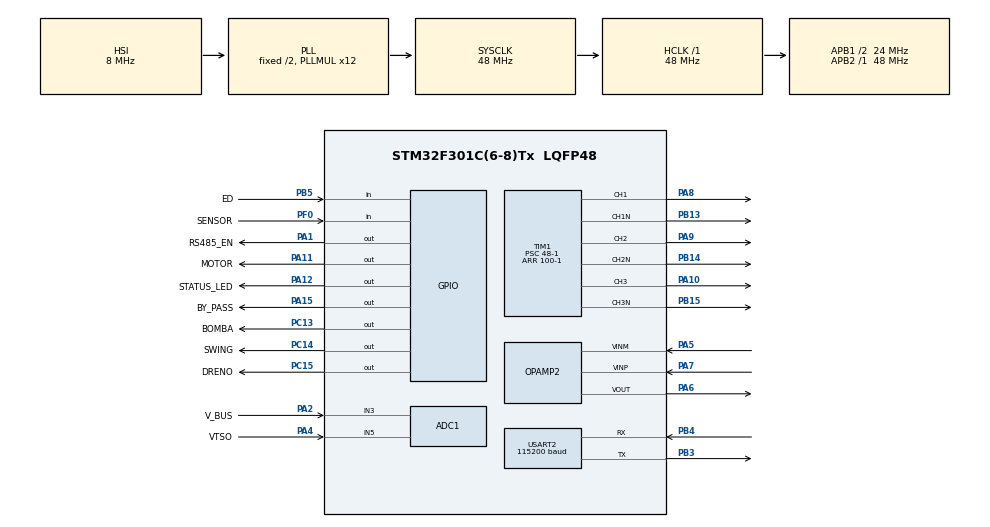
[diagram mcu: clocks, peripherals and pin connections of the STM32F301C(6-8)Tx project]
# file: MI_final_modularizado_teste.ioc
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ADC1.Channel-0\#ChannelRegularConversion=ADC_CHANNEL_5
ADC1.NbrOfConversionFlag=1
ADC1.Offset-0\#ChannelRegularConversion=0
ADC1.OffsetNumber-0\#ChannelRegularConversion=ADC_OFFSET_NONE
ADC1.Rank-0\#ChannelRegularConversion=1
ADC1.SamplingTime-0\#ChannelRegularConversion=ADC_SAMPLETIME_181CYCLES_5
ADC1.SamplingTimeOPAMP-0\#ChannelRegularConversion=ADC_SAMPLETIME_181CYCLES_5
ADC1.master=1
Dma.Request0=USART2_RX
Dma.USART2_RX.0.Direction=DMA_PERIPH_TO_MEMORY
Dma.USART2_RX.0.Instance=DMA1_Channel6
Dma.USART2_RX.0.MemDataAlignment=DMA_MDATAALIGN_BYTE
Dma.USART2_RX.0.MemInc=DMA_MINC_ENABLE
Dma.USART2_RX.0.Mode=DMA_NORMAL
Dma.USART2_RX.0.PeriphDataAlignment=DMA_PDATAALIGN_BYTE
Dma.USART2_RX.0.PeriphInc=DMA_PINC_DISABLE
Dma.USART2_RX.0.Priority=DMA_PRIORITY_LOW
Mcu.Family=STM32F3
Mcu.Name=STM32F301C(6-8)Tx
Mcu.Package=LQFP48
NVIC.DMA1_Channel6_IRQn=true\:0\:0\:false\:false\:true\:false\:true\:true
NVIC.PriorityGroup=NVIC_PRIORITYGROUP_4
NVIC.TIM1_UP_TIM16_IRQn=true\:0\:0\:false\:false\:true\:true\:true\:true
NVIC.TIM2_IRQn=true\:0\:0\:false\:false\:true\:true\:true\:true
NVIC.USART2_IRQn=true\:0\:0\:false\:false\:true\:true\:true\:true
PA1.GPIO_Label=RS485_EN
PA1.Signal=GPIO_Output
PA10.Signal=S_TIM1_CH3
PA11.GPIO_Label=MOTOR
PA11.GPIO_PuPd=GPIO_PULLDOWN
PA11.Signal=GPIO_Output
PA12.GPIO_Label=STATUS_LED
PA12.GPIO_PuPd=GPIO_NOPULL
PA12.Signal=GPIO_Output
PA13.Mode=Serial_Wire
PA13.Signal=SYS_JTMS-SWDIO
PA14.Mode=Serial_Wire
PA14.Signal=SYS_JTCK-SWCLK
PA15.GPIO_Label=BY_PASS
PA15.Signal=GPIO_Output
PA2.GPIO_Label=V_BUS
PA2.Mode=IN3-Single-Ended
PA2.Signal=ADC1_IN3
PA4.GPIO_Label=VTSO
PA4.Mode=IN5-Single-Ended
PA4.Signal=ADC1_IN5
PA5.Mode=Standalone
PA5.Signal=OPAMP2_VINM
PA6.Signal=SharedAnalog_PA6
PA7.Mode=Standalone
PA7.Signal=OPAMP2_VINP
PA8.Signal=S_TIM1_CH1
PA9.Signal=S_TIM1_CH2
PB13.Mode=PWM Generation1 CH1 CH1N
PB13.Signal=TIM1_CH1N
PB14.Mode=PWM Generation2 CH2 CH2N
PB14.Signal=TIM1_CH2N
PB15.Mode=PWM Generation3 CH3 CH3N
PB15.Signal=TIM1_CH3N
PB3.Mode=Asynchronous
PB3.Signal=USART2_TX
PB4.Mode=Asynchronous
PB4.Signal=USART2_RX
PB5.GPIO_Label=ED
PB5.Signal=GPIO_Input
PC13.GPIO_Label=BOMBA
PC13.GPIO_PuPd=GPIO_PULLDOWN
PC13.Signal=GPIO_Output
PC14\ -\ OSC32_IN.GPIO_Label=SWING
PC14\ -\ OSC32_IN.GPIO_PuPd=GPIO_PULLDOWN
PC14\ -\ OSC32_IN.Signal=GPIO_Output
PC15\ -\ OSC32_OUT.GPIO_Label=DRENO
PC15\ -\ OSC32_OUT.GPIO_PuPd=GPIO_PULLDOWN
PC15\ -\ OSC32_OUT.Signal=GPIO_Output
PF0-OSC_IN.GPIO_Label=SENSOR
PF0-OSC_IN.GPIO_PuPd=GPIO_PULLDOWN
PF0-OSC_IN.Signal=GPIO_Input
ProjectManager.HeapSize=0x200
ProjectManager.StackSize=0x400
ProjectManager.TargetToolchain=STM32CubeIDE
RCC.AHBFreq_Value=48000000
RCC.APB1CLKDivider=RCC_HCLK_DIV2
RCC.APB1Freq_Value=24000000
RCC.APB1TimFreq_Value=48000000
RCC.APB2Freq_Value=48000000
RCC.APB2TimFreq_Value=48000000
RCC.CortexFreq_Value=48000000
RCC.DATA_CACHE_ENABLE=1
RCC.HCLKFreq_Value=48000000
RCC.HSE_VALUE=8000000
RCC.HSI_VALUE=8000000
RCC.INSTRUCTION_CACHE_ENABLE=1
RCC.LSE_Drive_CapabilityArg=+LSE_Drive_Capability
RCC.LSE_VALUE=32768
RCC.PLLMUL=RCC_PLL_MUL12
RCC.SYSCLKFreq_VALUE=48000000
RCC.SYSCLKSourceVirtual=RCC_SYSCLKSOURCE_PLLCLK
SH.S_TIM1_CH1.0=TIM1_CH1,PWM Generation1 CH1 CH1N
SH.S_TIM1_CH2.0=TIM1_CH2,PWM Generation2 CH2 CH2N
SH.S_TIM1_CH3.0=TIM1_CH3,PWM Generation3 CH3 CH3N
SH.SharedAnalog_PA6.0=ADC1_IN10
SH.SharedAnalog_PA6.1=OPAMP2_VOUT,Standalone
TIM1.AutoReloadPreload=TIM_AUTORELOAD_PRELOAD_ENABLE
TIM1.Channel-PWM\ Generation1\ CH1\ CH1N=TIM_CHANNEL_1
TIM1.Channel-PWM\ Generation2\ CH2\ CH2N=TIM_CHANNEL_2
TIM1.Channel-PWM\ Generation3\ CH3\ CH3N=TIM_CHANNEL_3
TIM1.DeadTime=96
TIM1.Period=100-1
TIM1.Prescaler=48-1
TIM1.Pulse-PWM\ Generation1\ CH1\ CH1N=50
TIM1.Pulse-PWM\ Generation2\ CH2\ CH2N=50
TIM1.Pulse-PWM\ Generation3\ CH3\ CH3N=50
TIM16.Period=10000-1
TIM16.Prescaler=4800-1
TIM2.AutoReloadPreload=TIM_AUTORELOAD_PRELOAD_ENABLE
TIM2.Period=100-1
TIM2.Prescaler=48-1
USART2.BaudRate=115200
USART2.Parity=PARITY_EVEN
USART2.VirtualMode-Asynchronous=VM_ASYNC
USART2.WordLength=WORDLENGTH_9B
VP_ADC1_OPAMP_OUT2.Mode=IN10-OPAMP2-Single-Ended
VP_TIM16_VS_ClockSourceINT.Mode=Enable_Timer
VP_TIM2_VS_ClockSourceINT.Mode=Internal
board=custom

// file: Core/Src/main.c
/* USER CODE BEGIN Header */
/**
  ******************************************************************************
  * @file           : main.c
  * @brief          : Main program body
  ******************************************************************************
  * @attention
  *
  * Copyright (c) 2026 STMicroelectronics.
  * All rights reserved.
  *
  * This software is licensed under terms that can be found in the LICENSE file
  * in the root directory of this software component.
  * If no LICENSE file comes with this software, it is provided AS-IS.
  *
  ******************************************************************************
  */
/* USER CODE END Header */
#include "main.h"
#include "adc.h"
#include "dma.h"
#include "opamp.h"
#include "tim.h"
#include "usart.h"
#include "gpio.h"

/* USER CODE BEGIN Includes */
#include "mi_app.h"
/* USER CODE END Includes */

void SystemClock_Config(void);

int main(void)
{

  /* MCU Configuration--------------------------------------------------------*/

  /* Reset of all peripherals, Initializes the Flash interface and the Systick. */
  HAL_Init();

  /* Configure the system clock */
  SystemClock_Config();

  /* Initialize all configured peripherals */
  MX_GPIO_Init();
  MX_DMA_Init();
  MX_TIM1_Init();
  MX_TIM2_Init();
  MX_TIM16_Init();
  MX_USART2_UART_Init();
  MX_ADC1_Init();
  MX_OPAMP2_Init();
  /* USER CODE BEGIN 2 */
  mi_app_init();
  /* USER CODE END 2 */

  /* Infinite loop */
  /* USER CODE BEGIN WHILE */
  while (1)
  {
	mi_app_process();
    /* USER CODE END WHILE */

  }
}

void SystemClock_Config(void)
{
  RCC_OscInitTypeDef RCC_OscInitStruct = {0};
  RCC_ClkInitTypeDef RCC_ClkInitStruct = {0};
  RCC_PeriphCLKInitTypeDef PeriphClkInit = {0};

  /** Initializes the RCC Oscillators according to the specified parameters
  * in the RCC_OscInitTypeDef structure.
  */
  RCC_OscInitStruct.OscillatorType = RCC_OSCILLATORTYPE_HSI;
  RCC_OscInitStruct.HSIState = RCC_HSI_ON;
  RCC_OscInitStruct.HSICalibrationValue = RCC_HSICALIBRATION_DEFAULT;
  RCC_OscInitStruct.PLL.PLLState = RCC_PLL_ON;
  RCC_OscInitStruct.PLL.PLLSource = RCC_PLLSOURCE_HSI;
  RCC_OscInitStruct.PLL.PLLMUL = RCC_PLL_MUL12;
  if (HAL_RCC_OscConfig(&RCC_OscInitStruct) != HAL_OK)
  {
    Error_Handler();
  }

  /** Initializes the CPU, AHB and APB buses clocks
  */
  RCC_ClkInitStruct.ClockType = RCC_CLOCKTYPE_HCLK|RCC_CLOCKTYPE_SYSCLK
                              |RCC_CLOCKTYPE_PCLK1|RCC_CLOCKTYPE_PCLK2;
  RCC_ClkInitStruct.SYSCLKSource = RCC_SYSCLKSOURCE_PLLCLK;
  RCC_ClkInitStruct.AHBCLKDivider = RCC_SYSCLK_DIV1;
  RCC_ClkInitStruct.APB1CLKDivider = RCC_HCLK_DIV2;
  RCC_ClkInitStruct.APB2CLKDivider = RCC_HCLK_DIV1;

  if (HAL_RCC_ClockConfig(&RCC_ClkInitStruct, FLASH_LATENCY_1) != HAL_OK)
  {
    Error_Handler();
  }
  PeriphClkInit.PeriphClockSelection = RCC_PERIPHCLK_TIM1|RCC_PERIPHCLK_TIM16
                              |RCC_PERIPHCLK_ADC1;
  PeriphClkInit.Tim1ClockSelection = RCC_TIM1CLK_HCLK;
  PeriphClkInit.Tim16ClockSelection = RCC_TIM16CLK_HCLK;
  PeriphClkInit.Adc1ClockSelection = RCC_ADC1PLLCLK_DIV1;

  if (HAL_RCCEx_PeriphCLKConfig(&PeriphClkInit) != HAL_OK)
  {
    Error_Handler();
  }
}

/* USER CODE BEGIN 4 */
void HAL_TIM_PeriodElapsedCallback(TIM_HandleTypeDef *htim)
{
  mi_app_on_period_elapsed(htim);
}
/* USER CODE END 4 */

void Error_Handler(void)
{
  __disable_irq();
  while (1)
  {
  }
}
